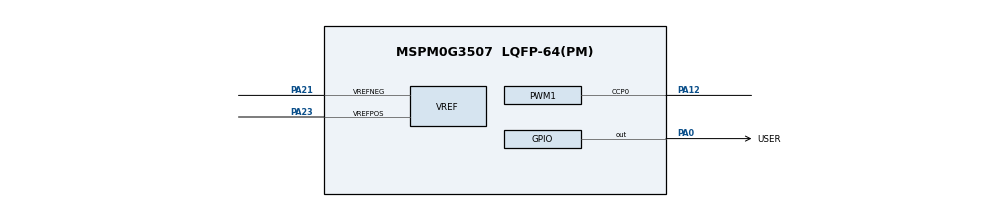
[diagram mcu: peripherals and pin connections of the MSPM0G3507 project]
/**
 * These arguments were used when this file was generated. They will be automatically applied on subsequent loads
 * via the GUI or CLI. Run CLI with '--help' for additional information on how to override these arguments.
 */
//@cliArgs --device "MSPM0G350X" --package "LQFP-64(PM)" --part "Default"
//@v2CliArgs --device "MSPM0G3507" --package "LQFP-64(PM)"
// @cliArgs --board /ti/boards/LP_MSPM0G3507 --rtos nortos

/**
 * Import the modules used in this configuration.
 */
const DAC12  = scripting.addModule("/ti/driverlib/DAC12");
const PWM    = scripting.addModule("/ti/driverlib/PWM", {}, false);
const PWM1   = PWM.addInstance();
const GPIO   = scripting.addModule("/ti/driverlib/GPIO", {}, false);
const SYSCTL = scripting.addModule("/ti/driverlib/SYSCTL");
const VREF   = scripting.addModule("/ti/driverlib/VREF");

/**
 * Write custom configuration values to the imported modules.
 */
const gate8  = system.clockTree["MFPCLKGATE"];
gate8.enable = true;

DAC12.dacOutputPinEn = true;
DAC12.dacAmplifier   = "ON";
DAC12.dacPosVREF     = "VEREFP";
DAC12.dacNegVREF     = "VEREFN";

/*
 * PWM_0 — single CC0 channel driving the native CCP0 + CCP0N outputs.
 *   CCP0  (PA12, J4 header) -> PWM   (Q2b gate, dummy path)
 *   CCP0N (PA13, J4 header) -> PWM_n (Q2a gate, laser path)
 *
 * CCP0N is the inverted output of the same compare event — intrinsic to
 * the CC0 subblock, not produced by the deadband generator. Both pins
 * flip on the same compare event, so the regulated current source Q1
 * always has a path through Q2a or Q2b (no shoot-through gap).
 *
 * Clock: BUSCLK = 32 MHz, prescale = 1
 * Period: 3200 counts -> 100 us (10 kHz), 50% duty cycle initially.
 */
PWM1.$name                          = "PWM_0";
PWM1.ccIndex                        = [0];
PWM1.ccIndexCmpl                    = [0];
PWM1.clockSource                    = "BUSCLK";
PWM1.clockPrescale                  = 1;
PWM1.timerCount                     = 3199;
PWM1.pwmMode                        = "EDGE_ALIGN";
PWM1.enableShadowLoad               = true;
PWM1.peripheral.$assign             = "TIMA0";
PWM1.peripheral.ccp0Pin.$assign     = "PA12";
PWM1.peripheral.ccp0Pin_cmpl.$assign = "PA13";
PWM1.PWM_CHANNEL_0.$name            = "ti_driverlib_pwm_PWMTimerCC0";
PWM1.PWM_CHANNEL_0.ccValue          = 1600;
PWM1.PWM_CHANNEL_0.shadowUpdateMode = "ZERO_EVT";
const GPIO_BLINK                              = GPIO.addInstance();
GPIO_BLINK.$name                              = "GPIO_BLINK";
GPIO_BLINK.associatedPins[0].$name            = "USER";
GPIO_BLINK.associatedPins[0].direction        = "OUTPUT";
GPIO_BLINK.associatedPins[0].pin.$assign      = "PA0";

const Board = scripting.addModule("/ti/driverlib/Board", {}, false);

SYSCTL.MFPCLKEn    = true;
SYSCTL.forceDefaultClkConfig = true;
SYSCTL.clockTreeEn  = true;

VREF.basicVrefPins                 = "VREF+-";
VREF.basicIntVolt                  = "DL_VREF_BUFCONFIG_OUTPUT_2_5V";
VREF.checkVREFReady                = true;
VREF.advClockConfigEnable          = true;
VREF.advClkSrc                     = "DL_VREF_CLOCK_BUSCLK";
VREF.peripheral.$assign            = "VREF";
VREF.peripheral.vrefPosPin.$assign = "PA23";
VREF.peripheral.vrefNegPin.$assign = "PA21";
